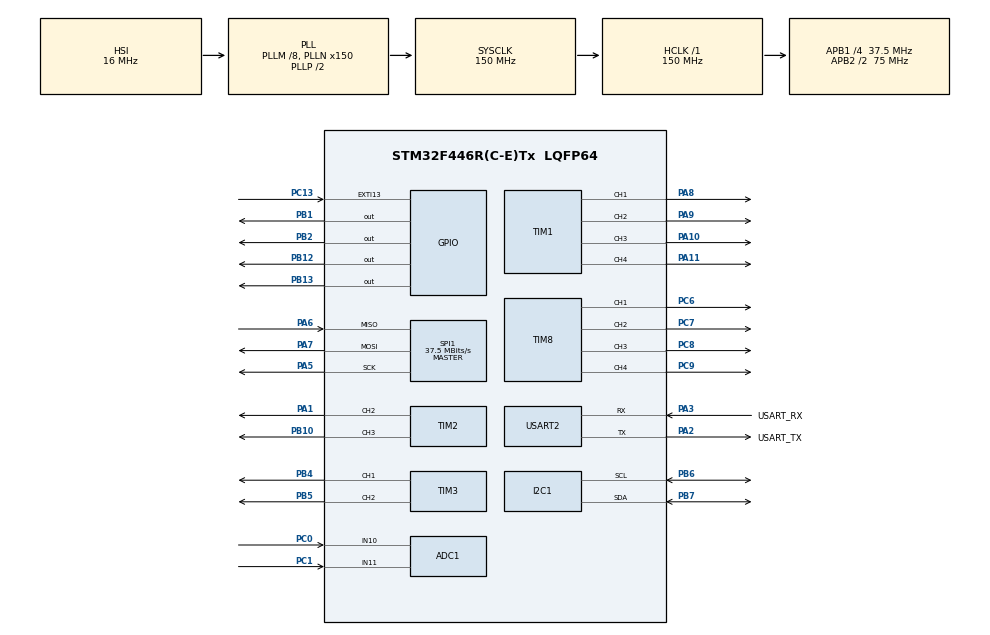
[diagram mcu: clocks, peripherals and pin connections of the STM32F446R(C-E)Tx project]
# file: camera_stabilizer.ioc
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ADC1.Channel-0\#ChannelRegularConversion=ADC_CHANNEL_10
ADC1.NbrOfConversionFlag=1
ADC1.Rank-0\#ChannelRegularConversion=1
ADC1.SamplingTime-0\#ChannelRegularConversion=ADC_SAMPLETIME_3CYCLES
ADC1.master=1
Dma.I2C1_RX.2.Direction=DMA_PERIPH_TO_MEMORY
Dma.I2C1_RX.2.FIFOMode=DMA_FIFOMODE_DISABLE
Dma.I2C1_RX.2.Instance=DMA1_Stream0
Dma.I2C1_RX.2.MemDataAlignment=DMA_MDATAALIGN_BYTE
Dma.I2C1_RX.2.MemInc=DMA_MINC_ENABLE
Dma.I2C1_RX.2.Mode=DMA_NORMAL
Dma.I2C1_RX.2.PeriphDataAlignment=DMA_PDATAALIGN_BYTE
Dma.I2C1_RX.2.PeriphInc=DMA_PINC_DISABLE
Dma.I2C1_RX.2.Priority=DMA_PRIORITY_HIGH
Dma.I2C1_TX.1.Direction=DMA_MEMORY_TO_PERIPH
Dma.I2C1_TX.1.FIFOMode=DMA_FIFOMODE_DISABLE
Dma.I2C1_TX.1.Instance=DMA1_Stream7
Dma.I2C1_TX.1.MemDataAlignment=DMA_MDATAALIGN_BYTE
Dma.I2C1_TX.1.MemInc=DMA_MINC_ENABLE
Dma.I2C1_TX.1.Mode=DMA_NORMAL
Dma.I2C1_TX.1.PeriphDataAlignment=DMA_PDATAALIGN_BYTE
Dma.I2C1_TX.1.PeriphInc=DMA_PINC_DISABLE
Dma.I2C1_TX.1.Priority=DMA_PRIORITY_HIGH
Dma.Request0=USART2_TX
Dma.Request1=I2C1_TX
Dma.Request2=I2C1_RX
Dma.USART2_TX.0.Direction=DMA_MEMORY_TO_PERIPH
Dma.USART2_TX.0.FIFOMode=DMA_FIFOMODE_DISABLE
Dma.USART2_TX.0.Instance=DMA1_Stream6
Dma.USART2_TX.0.MemDataAlignment=DMA_MDATAALIGN_BYTE
Dma.USART2_TX.0.MemInc=DMA_MINC_ENABLE
Dma.USART2_TX.0.Mode=DMA_NORMAL
Dma.USART2_TX.0.PeriphDataAlignment=DMA_PDATAALIGN_BYTE
Dma.USART2_TX.0.PeriphInc=DMA_PINC_DISABLE
Dma.USART2_TX.0.Priority=DMA_PRIORITY_LOW
FREERTOS.BinarySemaphores01=dmaTxCompleteSemaphore,Dynamic,NULL,Available
FREERTOS.Mutexes01=uartMutex,Dynamic,NULL,Available
FREERTOS.Queues01=MPU6050Data,10,MPU6050_Data,0,Dynamic,NULL,NULL;KalmanAngle,80,KalmanFilter,0,Dynamic,NULL,NULL
FREERTOS.Tasks01=MotorRun,40,512,motorRun,Default,NULL,Dynamic,NULL,NULL;MPU6050Task,24,512,mpu6050_ReadData,Default,NULL,Dynamic,NULL,NULL;DataProcessingT,16,512,DataProcessing,Default,NULL,Dynamic,NULL,NULL
FREERTOS.configENABLE_FPU=1
FREERTOS.configTOTAL_HEAP_SIZE=40960
I2C1.I2C_Mode=I2C_Fast
Mcu.Family=STM32F4
Mcu.Name=STM32F446R(C-E)Tx
Mcu.Package=LQFP64
NVIC.DMA1_Stream0_IRQn=true\:5\:0\:false\:false\:true\:true\:false\:true\:true
NVIC.DMA1_Stream6_IRQn=true\:5\:0\:false\:false\:true\:true\:false\:true\:true
NVIC.DMA1_Stream7_IRQn=true\:5\:0\:false\:false\:true\:true\:false\:true\:true
NVIC.EXTI15_10_IRQn=true\:5\:0\:false\:false\:true\:true\:true\:true\:true
NVIC.PriorityGroup=NVIC_PRIORITYGROUP_4
PA1.GPIO_Speed=GPIO_SPEED_FREQ_MEDIUM
PA1.Signal=S_TIM2_CH2
PA10.GPIO_Speed=GPIO_SPEED_FREQ_MEDIUM
PA10.Signal=S_TIM1_CH3
PA11.GPIO_Speed=GPIO_SPEED_FREQ_MEDIUM
PA11.Signal=S_TIM1_CH4
PA13.GPIO_Label=TMS
PA13.Mode=Serial_Wire
PA13.Signal=SYS_JTMS-SWDIO
PA14.GPIO_Label=TCK
PA14.Mode=Serial_Wire
PA14.Signal=SYS_JTCK-SWCLK
PA2.GPIO_Label=USART_TX
PA2.Mode=Asynchronous
PA2.Signal=USART2_TX
PA3.GPIO_Label=USART_RX
PA3.Mode=Asynchronous
PA3.Signal=USART2_RX
PA5.Mode=Full_Duplex_Master
PA5.Signal=SPI1_SCK
PA6.Mode=Full_Duplex_Master
PA6.Signal=SPI1_MISO
PA7.Mode=Full_Duplex_Master
PA7.Signal=SPI1_MOSI
PA8.GPIO_Speed=GPIO_SPEED_FREQ_MEDIUM
PA8.Signal=S_TIM1_CH1
PA9.GPIO_Speed=GPIO_SPEED_FREQ_MEDIUM
PA9.Signal=S_TIM1_CH2
PB1.Signal=GPIO_Output
PB10.Signal=S_TIM2_CH3
PB12.PinState=GPIO_PIN_RESET
PB12.Signal=GPIO_Output
PB13.GPIO_Speed=GPIO_SPEED_FREQ_LOW
PB13.Signal=GPIO_Output
PB2.PinState=GPIO_PIN_RESET
PB2.Signal=GPIO_Output
PB3.GPIO_Label=SWO
PB3.Signal=SYS_JTDO-SWO
PB4.GPIO_Speed=GPIO_SPEED_FREQ_MEDIUM
PB4.Signal=S_TIM3_CH1
PB5.GPIO_Speed=GPIO_SPEED_FREQ_MEDIUM
PB5.Signal=S_TIM3_CH2
PB6.GPIO_Pu=GPIO_NOPULL
PB6.Mode=I2C
PB6.Signal=I2C1_SCL
PB7.Mode=I2C
PB7.Signal=I2C1_SDA
PC0.Signal=ADCx_IN10
PC1.Signal=ADCx_IN11
PC13.Signal=GPXTI13
PC14-OSC32_IN.Mode=LSE-External-Oscillator
PC14-OSC32_IN.Signal=RCC_OSC32_IN
PC15-OSC32_OUT.Mode=LSE-External-Oscillator
PC15-OSC32_OUT.Signal=RCC_OSC32_OUT
PC6.GPIO_Speed=GPIO_SPEED_FREQ_MEDIUM
PC6.Signal=S_TIM8_CH1
PC7.GPIO_Speed=GPIO_SPEED_FREQ_MEDIUM
PC7.Signal=S_TIM8_CH2
PC8.GPIO_Speed=GPIO_SPEED_FREQ_MEDIUM
PC8.Signal=S_TIM8_CH3
PC9.GPIO_Speed=GPIO_SPEED_FREQ_MEDIUM
PC9.Signal=S_TIM8_CH4
PH0-OSC_IN.Mode=HSE-External-Oscillator
PH0-OSC_IN.Signal=RCC_OSC_IN
PH1-OSC_OUT.Mode=HSE-External-Oscillator
PH1-OSC_OUT.Signal=RCC_OSC_OUT
ProjectManager.HeapSize=0x200
ProjectManager.StackSize=0x400
ProjectManager.TargetToolchain=STM32CubeIDE
RCC.48MHZClocksFreq_Value=84000000
RCC.AHBFreq_Value=150000000
RCC.APB1CLKDivider=RCC_HCLK_DIV4
RCC.APB1Freq_Value=37500000
RCC.APB1TimFreq_Value=75000000
RCC.APB2CLKDivider=RCC_HCLK_DIV2
RCC.APB2Freq_Value=75000000
RCC.APB2TimFreq_Value=150000000
RCC.CortexFreq_Value=150000000
RCC.FLatency-AdvancedSettings=FLASH_LATENCY_4
RCC.HCLKFreq_Value=150000000
RCC.HSE_VALUE=8000000
RCC.HSI_VALUE=16000000
RCC.PLLM=8
RCC.PLLN=150
RCC.SYSCLKFreq_VALUE=150000000
RCC.SYSCLKSource=RCC_SYSCLKSOURCE_PLLCLK
RCC.USBFreq_Value=150000000
RCC.VCOOutputFreq_Value=300000000
SH.ADCx_IN10.0=ADC1_IN10,IN10
SH.ADCx_IN11.0=ADC1_IN11,IN11
SH.S_TIM1_CH1.0=TIM1_CH1,PWM Generation1 CH1
SH.S_TIM1_CH2.0=TIM1_CH2,PWM Generation2 CH2
SH.S_TIM1_CH3.0=TIM1_CH3,PWM Generation3 CH3
SH.S_TIM1_CH4.0=TIM1_CH4,PWM Generation4 CH4
SH.S_TIM2_CH2.0=TIM2_CH2,PWM Generation2 CH2
SH.S_TIM2_CH3.0=TIM2_CH3,PWM Generation3 CH3
SH.S_TIM3_CH1.0=TIM3_CH1,PWM Generation1 CH1
SH.S_TIM3_CH2.0=TIM3_CH2,PWM Generation2 CH2
SH.S_TIM8_CH1.0=TIM8_CH1,PWM Generation1 CH1
SH.S_TIM8_CH2.0=TIM8_CH2,PWM Generation2 CH2
SH.S_TIM8_CH3.0=TIM8_CH3,PWM Generation3 CH3
SH.S_TIM8_CH4.0=TIM8_CH4,PWM Generation4 CH4
SPI1.CalculateBaudRate=37.5 MBits/s
SPI1.Direction=SPI_DIRECTION_2LINES
SPI1.Mode=SPI_MODE_MASTER
SPI1.VirtualType=VM_MASTER
TIM1.Channel-PWM\ Generation1\ CH1=TIM_CHANNEL_1
TIM1.Channel-PWM\ Generation2\ CH2=TIM_CHANNEL_2
TIM1.Channel-PWM\ Generation3\ CH3=TIM_CHANNEL_3
TIM1.Channel-PWM\ Generation4\ CH4=TIM_CHANNEL_4
TIM2.Channel-PWM\ Generation2\ CH2=TIM_CHANNEL_2
TIM2.Channel-PWM\ Generation3\ CH3=TIM_CHANNEL_3
TIM3.Channel-PWM\ Generation1\ CH1=TIM_CHANNEL_1
TIM3.Channel-PWM\ Generation2\ CH2=TIM_CHANNEL_2
TIM8.Channel-PWM\ Generation1\ CH1=TIM_CHANNEL_1
TIM8.Channel-PWM\ Generation2\ CH2=TIM_CHANNEL_2
TIM8.Channel-PWM\ Generation3\ CH3=TIM_CHANNEL_3
TIM8.Channel-PWM\ Generation4\ CH4=TIM_CHANNEL_4
USART2.VirtualMode=VM_ASYNC
VP_FREERTOS_VS_CMSIS_V2.Mode=CMSIS_V2
VP_TIM1_VS_ClockSourceINT.Mode=Internal
VP_TIM2_VS_ClockSourceINT.Mode=Internal
VP_TIM3_VS_ClockSourceINT.Mode=Internal
VP_TIM8_VS_ClockSourceINT.Mode=Internal
board=NUCLEO-F446RE

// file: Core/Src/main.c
/* USER CODE BEGIN Header */
/**
  ******************************************************************************
  * @file           : main.c
  * @brief          : Main program body
  ******************************************************************************
  * @attention
  *
  * Copyright (c) 2025 STMicroelectronics.
  * All rights reserved.
  *
  * This software is licensed under terms that can be found in the LICENSE file
  * in the root directory of this software component.
  * If no LICENSE file comes with this software, it is provided AS-IS.
  *
  ******************************************************************************
  */
/* USER CODE END Header */
#include "main.h"
#include "cmsis_os.h"

/* USER CODE BEGIN Includes */
#include "motorControlPID.h"
#include "compute_angles.h"
#include "mpu6050.h"
#include "rtos_threads.h"
/* USER CODE END Includes */

/* USER CODE BEGIN PD */
#define PRESCALER_VALUE 1     // Prescaler value for 150 MHz clock
#define PWM_PERIOD 1499        // ARR value for 60 kHz PWM with 150 MHz clock
/* USER CODE END PD */

ADC_HandleTypeDef hadc1;

I2C_HandleTypeDef hi2c1;
DMA_HandleTypeDef hdma_i2c1_tx;
DMA_HandleTypeDef hdma_i2c1_rx;

SPI_HandleTypeDef hspi1;

TIM_HandleTypeDef htim1;
TIM_HandleTypeDef htim2;
TIM_HandleTypeDef htim3;
TIM_HandleTypeDef htim8;

UART_HandleTypeDef huart2;
DMA_HandleTypeDef hdma_usart2_tx;

/* Definitions for MotorRun */
osThreadId_t MotorRunHandle;
const osThreadAttr_t MotorRun_attributes = {
  .name = "MotorRun",
  .stack_size = 512 * 4,
  .priority = (osPriority_t) osPriorityNormal,
};
/* Definitions for MPU6050Task */
osThreadId_t MPU6050TaskHandle;
const osThreadAttr_t MPU6050Task_attributes = {
  .name = "MPU6050Task",
  .stack_size = 512 * 4,
  .priority = (osPriority_t) osPriorityNormal,
};
/* Definitions for DataProcessingT */
osThreadId_t DataProcessingTHandle;
const osThreadAttr_t DataProcessingT_attributes = {
  .name = "DataProcessingT",
  .stack_size = 512 * 4,
  .priority = (osPriority_t) osPriorityHigh,
};
/* Definitions for MPU6050Data */
osMessageQueueId_t MPU6050DataHandle;
const osMessageQueueAttr_t MPU6050Data_attributes = {
  .name = "MPU6050Data"
};
/* Definitions for KalmanAngle */
osMessageQueueId_t KalmanAngleHandle;
const osMessageQueueAttr_t KalmanAngle_attributes = {
  .name = "KalmanAngle"
};
/* Definitions for uartMutex */
osMutexId_t uartMutexHandle;
const osMutexAttr_t uartMutex_attributes = {
  .name = "uartMutex"
};
/* Definitions for dmaTxCompleteSemaphore */
osSemaphoreId_t dmaTxCompleteSemaphoreHandle;
const osSemaphoreAttr_t dmaTxCompleteSemaphore_attributes = {
  .name = "dmaTxCompleteSemaphore"
};

void SystemClock_Config(void);
static void MX_GPIO_Init(void);
static void MX_DMA_Init(void);
static void MX_USART2_UART_Init(void);
static void MX_I2C1_Init(void);
static void MX_SPI1_Init(void);
static void MX_ADC1_Init(void);
static void MX_TIM1_Init(void);
static void MX_TIM2_Init(void);
static void MX_TIM3_Init(void);
static void MX_TIM8_Init(void);
void motorRun(void *argument);
void mpu6050_ReadData(void *argument);
void DataProcessing(void *argument);

int main(void)
{

  /* MCU Configuration--------------------------------------------------------*/

  /* Reset of all peripherals, Initializes the Flash interface and the Systick. */
  HAL_Init();

  /* Configure the system clock */
  SystemClock_Config();

  /* Initialize all configured peripherals */
  MX_GPIO_Init();
  MX_DMA_Init();
  MX_USART2_UART_Init();
  MX_I2C1_Init();
  MX_SPI1_Init();
  MX_ADC1_Init();
  MX_TIM1_Init();
  MX_TIM2_Init();
  MX_TIM3_Init();
  MX_TIM8_Init();

  /* Init scheduler */
  osKernelInitialize();
  /* Create the mutex(es) */
  /* creation of uartMutex */
  uartMutexHandle = osMutexNew(&uartMutex_attributes);

  /* USER CODE BEGIN RTOS_MUTEX */
  if (uartMutexHandle == NULL) {
      // Error handling if the mutex creation fails
      printf("Failed to create UART mutex\r\n");
  }
  /* add mutexes, ... */
  /* USER CODE END RTOS_MUTEX */

  /* Create the semaphores(s) */
  /* creation of dmaTxCompleteSemaphore */
  dmaTxCompleteSemaphoreHandle = osSemaphoreNew(1, 1, &dmaTxCompleteSemaphore_attributes);

  /* USER CODE BEGIN RTOS_SEMAPHORES */
  if (dmaTxCompleteSemaphoreHandle == NULL) {
      // Error handling if the semaphore creation fails
      printf("Failed to create DMA TX complete semaphore\r\n");
  }
  /* add semaphores, ... */
  /* USER CODE END RTOS_SEMAPHORES */

  /* Create the queue(s) */
  /* creation of MPU6050Data */
  MPU6050DataHandle = osMessageQueueNew (10, sizeof(MPU6050_Data), &MPU6050Data_attributes);

  /* creation of KalmanAngle */
  KalmanAngleHandle = osMessageQueueNew (10, sizeof(float), &KalmanAngle_attributes);

  /* Create the thread(s) */
  /* creation of MotorRun */
  MotorRunHandle = osThreadNew(motorRun, NULL, &MotorRun_attributes);

  /* creation of MPU6050Task */
  MPU6050TaskHandle = osThreadNew(mpu6050_ReadData, NULL, &MPU6050Task_attributes);

  /* creation of DataProcessingT */
  DataProcessingTHandle = osThreadNew(DataProcessing, NULL, &DataProcessingT_attributes);

  /* Start scheduler */
  osKernelStart();

  /* We should never get here as control is now taken by the scheduler */

  /* Infinite loop */
  while (1)
  {

  }
}

void SystemClock_Config(void)
{
  RCC_OscInitTypeDef RCC_OscInitStruct = {0};
  RCC_ClkInitTypeDef RCC_ClkInitStruct = {0};

  /** Configure the main internal regulator output voltage
  */
  __HAL_RCC_PWR_CLK_ENABLE();
  __HAL_PWR_VOLTAGESCALING_CONFIG(PWR_REGULATOR_VOLTAGE_SCALE1);

  /** Initializes the RCC Oscillators according to the specified parameters
  * in the RCC_OscInitTypeDef structure.
  */
  RCC_OscInitStruct.OscillatorType = RCC_OSCILLATORTYPE_HSI;
  RCC_OscInitStruct.HSIState = RCC_HSI_ON;
  RCC_OscInitStruct.HSICalibrationValue = RCC_HSICALIBRATION_DEFAULT;
  RCC_OscInitStruct.PLL.PLLState = RCC_PLL_ON;
  RCC_OscInitStruct.PLL.PLLSource = RCC_PLLSOURCE_HSI;
  RCC_OscInitStruct.PLL.PLLM = 8;
  RCC_OscInitStruct.PLL.PLLN = 150;
  RCC_OscInitStruct.PLL.PLLP = RCC_PLLP_DIV2;
  RCC_OscInitStruct.PLL.PLLQ = 2;
  RCC_OscInitStruct.PLL.PLLR = 2;
  if (HAL_RCC_OscConfig(&RCC_OscInitStruct) != HAL_OK)
  {
    Error_Handler();
  }

  /** Initializes the CPU, AHB and APB buses clocks
  */
  RCC_ClkInitStruct.ClockType = RCC_CLOCKTYPE_HCLK|RCC_CLOCKTYPE_SYSCLK
                              |RCC_CLOCKTYPE_PCLK1|RCC_CLOCKTYPE_PCLK2;
  RCC_ClkInitStruct.SYSCLKSource = RCC_SYSCLKSOURCE_PLLCLK;
  RCC_ClkInitStruct.AHBCLKDivider = RCC_SYSCLK_DIV1;
  RCC_ClkInitStruct.APB1CLKDivider = RCC_HCLK_DIV4;
  RCC_ClkInitStruct.APB2CLKDivider = RCC_HCLK_DIV2;

  if (HAL_RCC_ClockConfig(&RCC_ClkInitStruct, FLASH_LATENCY_4) != HAL_OK)
  {
    Error_Handler();
  }
}

static void MX_ADC1_Init(void)
{

  ADC_ChannelConfTypeDef sConfig = {0};

  /** Configure the global features of the ADC (Clock, Resolution, Data Alignment and number of conversion)
  */
  hadc1.Instance = ADC1;
  hadc1.Init.ClockPrescaler = ADC_CLOCK_SYNC_PCLK_DIV4;
  hadc1.Init.Resolution = ADC_RESOLUTION_12B;
  hadc1.Init.ScanConvMode = DISABLE;
  hadc1.Init.ContinuousConvMode = DISABLE;
  hadc1.Init.DiscontinuousConvMode = DISABLE;
  hadc1.Init.ExternalTrigConvEdge = ADC_EXTERNALTRIGCONVEDGE_NONE;
  hadc1.Init.ExternalTrigConv = ADC_SOFTWARE_START;
  hadc1.Init.DataAlign = ADC_DATAALIGN_RIGHT;
  hadc1.Init.NbrOfConversion = 1;
  hadc1.Init.DMAContinuousRequests = DISABLE;
  hadc1.Init.EOCSelection = ADC_EOC_SINGLE_CONV;
  if (HAL_ADC_Init(&hadc1) != HAL_OK)
  {
    Error_Handler();
  }

  /** Configure for the selected ADC regular channel its corresponding rank in the sequencer and its sample time.
  */
  sConfig.Channel = ADC_CHANNEL_10;
  sConfig.Rank = 1;
  sConfig.SamplingTime = ADC_SAMPLETIME_3CYCLES;
  if (HAL_ADC_ConfigChannel(&hadc1, &sConfig) != HAL_OK)
  {
    Error_Handler();
  }

}

static void MX_I2C1_Init(void)
{

  hi2c1.Instance = I2C1;
  hi2c1.Init.ClockSpeed = 400000;
  hi2c1.Init.DutyCycle = I2C_DUTYCYCLE_2;
  hi2c1.Init.OwnAddress1 = 0;
  hi2c1.Init.AddressingMode = I2C_ADDRESSINGMODE_7BIT;
  hi2c1.Init.DualAddressMode = I2C_DUALADDRESS_DISABLE;
  hi2c1.Init.OwnAddress2 = 0;
  hi2c1.Init.GeneralCallMode = I2C_GENERALCALL_DISABLE;
  hi2c1.Init.NoStretchMode = I2C_NOSTRETCH_DISABLE;
  if (HAL_I2C_Init(&hi2c1) != HAL_OK)
  {
    Error_Handler();
  }

}

static void MX_SPI1_Init(void)
{

  /* SPI1 parameter configuration*/
  hspi1.Instance = SPI1;
  hspi1.Init.Mode = SPI_MODE_MASTER;
  hspi1.Init.Direction = SPI_DIRECTION_2LINES;
  hspi1.Init.DataSize = SPI_DATASIZE_8BIT;
  hspi1.Init.CLKPolarity = SPI_POLARITY_LOW;
  hspi1.Init.CLKPhase = SPI_PHASE_1EDGE;
  hspi1.Init.NSS = SPI_NSS_SOFT;
  hspi1.Init.BaudRatePrescaler = SPI_BAUDRATEPRESCALER_2;
  hspi1.Init.FirstBit = SPI_FIRSTBIT_MSB;
  hspi1.Init.TIMode = SPI_TIMODE_DISABLE;
  hspi1.Init.CRCCalculation = SPI_CRCCALCULATION_DISABLE;
  hspi1.Init.CRCPolynomial = 10;
  if (HAL_SPI_Init(&hspi1) != HAL_OK)
  {
    Error_Handler();
  }

}

static void MX_TIM1_Init(void)
{

  TIM_ClockConfigTypeDef sClockSourceConfig = {0};
  TIM_MasterConfigTypeDef sMasterConfig = {0};
  TIM_OC_InitTypeDef sConfigOC = {0};
  TIM_BreakDeadTimeConfigTypeDef sBreakDeadTimeConfig = {0};

  htim1.Instance = TIM1;
  htim1.Init.Prescaler = PRESCALER_VALUE - 1;
  htim1.Init.CounterMode = TIM_COUNTERMODE_UP;
  htim1.Init.Period = PWM_PERIOD;
  htim1.Init.ClockDivision = TIM_CLOCKDIVISION_DIV1;
  htim1.Init.RepetitionCounter = 0;
  htim1.Init.AutoReloadPreload = TIM_AUTORELOAD_PRELOAD_DISABLE;
  if (HAL_TIM_Base_Init(&htim1) != HAL_OK)
  {
    Error_Handler();
  }
  sClockSourceConfig.ClockSource = TIM_CLOCKSOURCE_INTERNAL;
  if (HAL_TIM_ConfigClockSource(&htim1, &sClockSourceConfig) != HAL_OK)
  {
    Error_Handler();
  }
  if (HAL_TIM_PWM_Init(&htim1) != HAL_OK)
  {
    Error_Handler();
  }
  sMasterConfig.MasterOutputTrigger = TIM_TRGO_RESET;
  sMasterConfig.MasterSlaveMode = TIM_MASTERSLAVEMODE_DISABLE;
  if (HAL_TIMEx_MasterConfigSynchronization(&htim1, &sMasterConfig) != HAL_OK)
  {
    Error_Handler();
  }
  sConfigOC.OCMode = TIM_OCMODE_PWM1;
  sConfigOC.Pulse = 0;
  sConfigOC.OCPolarity = TIM_OCPOLARITY_HIGH;
  sConfigOC.OCNPolarity = TIM_OCNPOLARITY_HIGH;
  sConfigOC.OCFastMode = TIM_OCFAST_DISABLE;
  sConfigOC.OCIdleState = TIM_OCIDLESTATE_RESET;
  sConfigOC.OCNIdleState = TIM_OCNIDLESTATE_RESET;
  if (HAL_TIM_PWM_ConfigChannel(&htim1, &sConfigOC, TIM_CHANNEL_1) != HAL_OK)
  {
    Error_Handler();
  }
  if (HAL_TIM_PWM_ConfigChannel(&htim1, &sConfigOC, TIM_CHANNEL_2) != HAL_OK)
  {
    Error_Handler();
  }
  if (HAL_TIM_PWM_ConfigChannel(&htim1, &sConfigOC, TIM_CHANNEL_3) != HAL_OK)
  {
    Error_Handler();
  }
  if (HAL_TIM_PWM_ConfigChannel(&htim1, &sConfigOC, TIM_CHANNEL_4) != HAL_OK)
  {
    Error_Handler();
  }
  sBreakDeadTimeConfig.OffStateRunMode = TIM_OSSR_DISABLE;
  sBreakDeadTimeConfig.OffStateIDLEMode = TIM_OSSI_DISABLE;
  sBreakDeadTimeConfig.LockLevel = TIM_LOCKLEVEL_OFF;
  sBreakDeadTimeConfig.DeadTime = 0;
  sBreakDeadTimeConfig.BreakState = TIM_BREAK_DISABLE;
  sBreakDeadTimeConfig.BreakPolarity = TIM_BREAKPOLARITY_HIGH;
  sBreakDeadTimeConfig.AutomaticOutput = TIM_AUTOMATICOUTPUT_DISABLE;
  if (HAL_TIMEx_ConfigBreakDeadTime(&htim1, &sBreakDeadTimeConfig) != HAL_OK)
  {
    Error_Handler();
  }
  HAL_TIM_MspPostInit(&htim1);

}

static void MX_TIM2_Init(void)
{

  TIM_ClockConfigTypeDef sClockSourceConfig = {0};
  TIM_MasterConfigTypeDef sMasterConfig = {0};
  TIM_OC_InitTypeDef sConfigOC = {0};

  htim2.Instance = TIM2;
  htim2.Init.Prescaler = PRESCALER_VALUE - 1;
  htim2.Init.CounterMode = TIM_COUNTERMODE_UP;
  htim2.Init.Period = PWM_PERIOD;
  htim2.Init.ClockDivision = TIM_CLOCKDIVISION_DIV1;
  htim2.Init.AutoReloadPreload = TIM_AUTORELOAD_PRELOAD_DISABLE;
  if (HAL_TIM_Base_Init(&htim2) != HAL_OK)
  {
    Error_Handler();
  }
  sClockSourceConfig.ClockSource = TIM_CLOCKSOURCE_INTERNAL;
  if (HAL_TIM_ConfigClockSource(&htim2, &sClockSourceConfig) != HAL_OK)
  {
    Error_Handler();
  }
  if (HAL_TIM_PWM_Init(&htim2) != HAL_OK)
  {
    Error_Handler();
  }
  sMasterConfig.MasterOutputTrigger = TIM_TRGO_RESET;
  sMasterConfig.MasterSlaveMode = TIM_MASTERSLAVEMODE_DISABLE;
  if (HAL_TIMEx_MasterConfigSynchronization(&htim2, &sMasterConfig) != HAL_OK)
  {
    Error_Handler();
  }
  sConfigOC.OCMode = TIM_OCMODE_PWM1;
  sConfigOC.Pulse = 0;
  sConfigOC.OCPolarity = TIM_OCPOLARITY_HIGH;
  sConfigOC.OCFastMode = TIM_OCFAST_DISABLE;
  if (HAL_TIM_PWM_ConfigChannel(&htim2, &sConfigOC, TIM_CHANNEL_2) != HAL_OK)
  {
    Error_Handler();
  }
  if (HAL_TIM_PWM_ConfigChannel(&htim2, &sConfigOC, TIM_CHANNEL_3) != HAL_OK)
  {
    Error_Handler();
  }
  HAL_TIM_MspPostInit(&htim2);

}

static void MX_TIM3_Init(void)
{

  TIM_ClockConfigTypeDef sClockSourceConfig = {0};
  TIM_MasterConfigTypeDef sMasterConfig = {0};
  TIM_OC_InitTypeDef sConfigOC = {0};

  htim3.Instance = TIM3;
  htim3.Init.Prescaler = PRESCALER_VALUE - 1;
  htim3.Init.CounterMode = TIM_COUNTERMODE_UP;
  htim3.Init.Period = PWM_PERIOD;
  htim3.Init.ClockDivision = TIM_CLOCKDIVISION_DIV1;
  htim3.Init.AutoReloadPreload = TIM_AUTORELOAD_PRELOAD_DISABLE;
  if (HAL_TIM_Base_Init(&htim3) != HAL_OK)
  {
    Error_Handler();
  }
  sClockSourceConfig.ClockSource = TIM_CLOCKSOURCE_INTERNAL;
  if (HAL_TIM_ConfigClockSource(&htim3, &sClockSourceConfig) != HAL_OK)
  {
    Error_Handler();
  }
  if (HAL_TIM_PWM_Init(&htim3) != HAL_OK)
  {
    Error_Handler();
  }
  sMasterConfig.MasterOutputTrigger = TIM_TRGO_RESET;
  sMasterConfig.MasterSlaveMode = TIM_MASTERSLAVEMODE_DISABLE;
  if (HAL_TIMEx_MasterConfigSynchronization(&htim3, &sMasterConfig) != HAL_OK)
  {
    Error_Handler();
  }
  sConfigOC.OCMode = TIM_OCMODE_PWM1;
  sConfigOC.Pulse = 0;
  sConfigOC.OCPolarity = TIM_OCPOLARITY_HIGH;
  sConfigOC.OCFastMode = TIM_OCFAST_DISABLE;
  if (HAL_TIM_PWM_ConfigChannel(&htim3, &sConfigOC, TIM_CHANNEL_1) != HAL_OK)
  {
    Error_Handler();
  }
  if (HAL_TIM_PWM_ConfigChannel(&htim3, &sConfigOC, TIM_CHANNEL_2) != HAL_OK)
  {
    Error_Handler();
  }
  HAL_TIM_MspPostInit(&htim3);

}

static void MX_TIM8_Init(void)
{

  TIM_ClockConfigTypeDef sClockSourceConfig = {0};
  TIM_MasterConfigTypeDef sMasterConfig = {0};
  TIM_OC_InitTypeDef sConfigOC = {0};
  TIM_BreakDeadTimeConfigTypeDef sBreakDeadTimeConfig = {0};

  htim8.Instance = TIM8;
  htim8.Init.Prescaler = PRESCALER_VALUE - 1;
  htim8.Init.CounterMode = TIM_COUNTERMODE_UP;
  htim8.Init.Period = PWM_PERIOD;
  htim8.Init.ClockDivision = TIM_CLOCKDIVISION_DIV1;
  htim8.Init.RepetitionCounter = 0;
  htim8.Init.AutoReloadPreload = TIM_AUTORELOAD_PRELOAD_DISABLE;
  if (HAL_TIM_Base_Init(&htim8) != HAL_OK)
  {
    Error_Handler();
  }
  sClockSourceConfig.ClockSource = TIM_CLOCKSOURCE_INTERNAL;
  if (HAL_TIM_ConfigClockSource(&htim8, &sClockSourceConfig) != HAL_OK)
  {
    Error_Handler();
  }
  if (HAL_TIM_PWM_Init(&htim8) != HAL_OK)
  {
    Error_Handler();
  }
  sMasterConfig.MasterOutputTrigger = TIM_TRGO_RESET;
  sMasterConfig.MasterSlaveMode = TIM_MASTERSLAVEMODE_DISABLE;
  if (HAL_TIMEx_MasterConfigSynchronization(&htim8, &sMasterConfig) != HAL_OK)
  {
    Error_Handler();
  }
  sConfigOC.OCMode = TIM_OCMODE_PWM1;
  sConfigOC.Pulse = 0;
  sConfigOC.OCPolarity = TIM_OCPOLARITY_HIGH;
  sConfigOC.OCNPolarity = TIM_OCNPOLARITY_HIGH;
  sConfigOC.OCFastMode = TIM_OCFAST_DISABLE;
  sConfigOC.OCIdleState = TIM_OCIDLESTATE_RESET;
  sConfigOC.OCNIdleState = TIM_OCNIDLESTATE_RESET;
  if (HAL_TIM_PWM_ConfigChannel(&htim8, &sConfigOC, TIM_CHANNEL_1) != HAL_OK)
  {
    Error_Handler();
  }
  if (HAL_TIM_PWM_ConfigChannel(&htim8, &sConfigOC, TIM_CHANNEL_2) != HAL_OK)
  {
    Error_Handler();
  }
  if (HAL_TIM_PWM_ConfigChannel(&htim8, &sConfigOC, TIM_CHANNEL_3) != HAL_OK)
  {
    Error_Handler();
  }
  if (HAL_TIM_PWM_ConfigChannel(&htim8, &sConfigOC, TIM_CHANNEL_4) != HAL_OK)
  {
    Error_Handler();
  }
  sBreakDeadTimeConfig.OffStateRunMode = TIM_OSSR_DISABLE;
  sBreakDeadTimeConfig.OffStateIDLEMode = TIM_OSSI_DISABLE;
  sBreakDeadTimeConfig.LockLevel = TIM_LOCKLEVEL_OFF;
  sBreakDeadTimeConfig.DeadTime = 0;
  sBreakDeadTimeConfig.BreakState = TIM_BREAK_DISABLE;
  sBreakDeadTimeConfig.BreakPolarity = TIM_BREAKPOLARITY_HIGH;
  sBreakDeadTimeConfig.AutomaticOutput = TIM_AUTOMATICOUTPUT_DISABLE;
  if (HAL_TIMEx_ConfigBreakDeadTime(&htim8, &sBreakDeadTimeConfig) != HAL_OK)
  {
    Error_Handler();
  }
  HAL_TIM_MspPostInit(&htim8);

}

static void MX_USART2_UART_Init(void)
{

  huart2.Instance = USART2;
  huart2.Init.BaudRate = 115200;
  huart2.Init.WordLength = UART_WORDLENGTH_8B;
  huart2.Init.StopBits = UART_STOPBITS_1;
  huart2.Init.Parity = UART_PARITY_NONE;
  huart2.Init.Mode = UART_MODE_TX_RX;
  huart2.Init.HwFlowCtl = UART_HWCONTROL_NONE;
  huart2.Init.OverSampling = UART_OVERSAMPLING_16;
  if (HAL_UART_Init(&huart2) != HAL_OK)
  {
    Error_Handler();
  }

}

static void MX_DMA_Init(void)
{

  /* DMA controller clock enable */
  __HAL_RCC_DMA1_CLK_ENABLE();

  /* DMA interrupt init */
  /* DMA1_Stream0_IRQn interrupt configuration */
  HAL_NVIC_SetPriority(DMA1_Stream0_IRQn, 5, 0);
  HAL_NVIC_EnableIRQ(DMA1_Stream0_IRQn);
  /* DMA1_Stream6_IRQn interrupt configuration */
  HAL_NVIC_SetPriority(DMA1_Stream6_IRQn, 5, 0);
  HAL_NVIC_EnableIRQ(DMA1_Stream6_IRQn);
  /* DMA1_Stream7_IRQn interrupt configuration */
  HAL_NVIC_SetPriority(DMA1_Stream7_IRQn, 5, 0);
  HAL_NVIC_EnableIRQ(DMA1_Stream7_IRQn);

}

static void MX_GPIO_Init(void)
{
  GPIO_InitTypeDef GPIO_InitStruct = {0};

  /* GPIO Ports Clock Enable */
  __HAL_RCC_GPIOC_CLK_ENABLE();
  __HAL_RCC_GPIOH_CLK_ENABLE();
  __HAL_RCC_GPIOA_CLK_ENABLE();
  __HAL_RCC_GPIOB_CLK_ENABLE();

  /*Configure GPIO pin Output Level */
  HAL_GPIO_WritePin(GPIOB, GPIO_PIN_1|GPIO_PIN_2|GPIO_PIN_12|GPIO_PIN_13, GPIO_PIN_RESET);

  /*Configure GPIO pin : PC13 */
  GPIO_InitStruct.Pin = GPIO_PIN_13;
  GPIO_InitStruct.Mode = GPIO_MODE_IT_RISING;
  GPIO_InitStruct.Pull = GPIO_NOPULL;
  HAL_GPIO_Init(GPIOC, &GPIO_InitStruct);

  /*Configure GPIO pins : PB1 PB2 PB12 PB13 */
  GPIO_InitStruct.Pin = GPIO_PIN_1|GPIO_PIN_2|GPIO_PIN_12|GPIO_PIN_13;
  GPIO_InitStruct.Mode = GPIO_MODE_OUTPUT_PP;
  GPIO_InitStruct.Pull = GPIO_NOPULL;
  GPIO_InitStruct.Speed = GPIO_SPEED_FREQ_LOW;
  HAL_GPIO_Init(GPIOB, &GPIO_InitStruct);

  /* EXTI interrupt init*/
  HAL_NVIC_SetPriority(EXTI15_10_IRQn, 5, 0);
  HAL_NVIC_EnableIRQ(EXTI15_10_IRQn);

}

void Error_Handler(void)
{
  __disable_irq();
  while (1)
  {
  }
}
